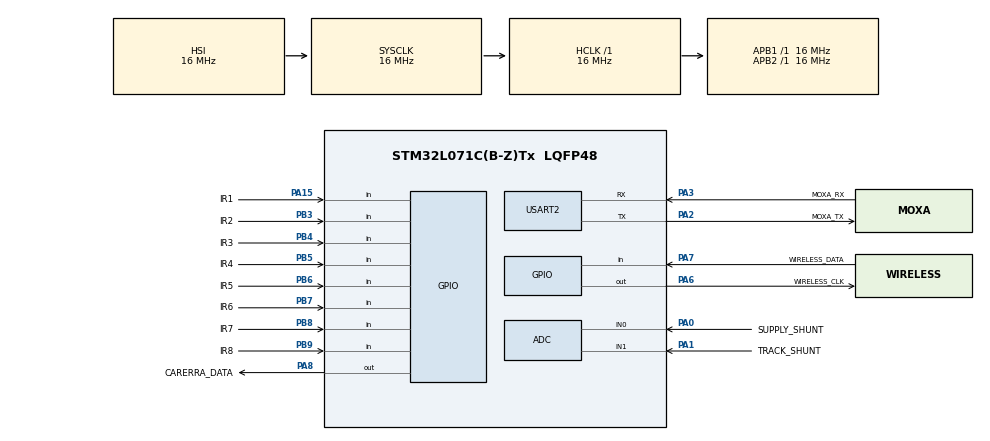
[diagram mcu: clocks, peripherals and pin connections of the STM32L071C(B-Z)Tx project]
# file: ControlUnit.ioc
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ADC.ClockPrescaler=ADC_CLOCK_SYNC_PCLK_DIV2
ADC.DMAContinuousRequests=ENABLE
ADC.ExternalTrigConv=ADC_EXTERNALTRIGCONV_T2_CC4
ADC.LowPowerFrequencyMode=DISABLE
ADC.Overrun=ADC_OVR_DATA_OVERWRITTEN
ADC.SamplingTime=ADC_SAMPLETIME_79CYCLES_5
Dma.ADC.0.Direction=DMA_PERIPH_TO_MEMORY
Dma.ADC.0.Instance=DMA1_Channel1
Dma.ADC.0.MemDataAlignment=DMA_MDATAALIGN_HALFWORD
Dma.ADC.0.MemInc=DMA_MINC_ENABLE
Dma.ADC.0.Mode=DMA_CIRCULAR
Dma.ADC.0.PeriphDataAlignment=DMA_PDATAALIGN_HALFWORD
Dma.ADC.0.PeriphInc=DMA_PINC_DISABLE
Dma.ADC.0.Priority=DMA_PRIORITY_LOW
Dma.Request0=ADC
Mcu.Family=STM32L0
Mcu.Name=STM32L071C(B-Z)Tx
Mcu.Package=LQFP48
NVIC.DMA1_Channel1_IRQn=true\:0\:0\:false\:false\:true\:false\:true\:true
NVIC.USART2_IRQn=true\:0\:0\:false\:false\:true\:true\:true\:true
PA0.GPIO_Label=SUPPLY_SHUNT
PA0.Mode=IN0
PA0.Signal=ADC_IN0
PA1.GPIO_Label=TRACK_SHUNT
PA1.Mode=IN1
PA1.Signal=ADC_IN1
PA15.GPIO_Label=IR1
PA15.Signal=GPIO_Input
PA2.GPIO_Label=MOXA_TX
PA2.Mode=Asynchronous
PA2.Signal=USART2_TX
PA3.GPIO_Label=MOXA_RX
PA3.Mode=Asynchronous
PA3.Signal=USART2_RX
PA6.GPIO_Label=WIRELESS_CLK
PA6.Signal=GPIO_Output
PA7.GPIO_Label=WIRELESS_DATA
PA7.Signal=GPIO_Input
PA8.GPIO_Label=CARERRA_DATA
PA8.Signal=GPIO_Output
PB3.GPIO_Label=IR2
PB3.Signal=GPIO_Input
PB4.GPIO_Label=IR3
PB4.Signal=GPIO_Input
PB5.GPIO_Label=IR4
PB5.Signal=GPIO_Input
PB6.GPIO_Label=IR5
PB6.Signal=GPIO_Input
PB7.GPIO_Label=IR6
PB7.Signal=GPIO_Input
PB8.GPIO_Label=IR7
PB8.Signal=GPIO_Input
PB9.GPIO_Label=IR8
PB9.Signal=GPIO_Input
ProjectManager.HeapSize=0x200
ProjectManager.StackSize=0x400
ProjectManager.TargetToolchain=CMake
RCC.AHBFreq_Value=16000000
RCC.APB1Freq_Value=16000000
RCC.APB1TimFreq_Value=16000000
RCC.APB2Freq_Value=16000000
RCC.APB2TimFreq_Value=16000000
RCC.HSE_VALUE=8000000
RCC.HSI16_VALUE=16000000
RCC.HSI_VALUE=16000000
RCC.LSE_VALUE=32768
RCC.MSI_VALUE=2097000
RCC.SYSCLKFreq_VALUE=16000000
RCC.SYSCLKSource=RCC_SYSCLKSOURCE_HSI
RCC.VCOOutputFreq_Value=48000000
TIM2.Channel-Output\ Compare4\ No\ Output=TIM_CHANNEL_4
TIM2.Period=65535
TIM2.Prescaler=15
TIM2.Pulse-Output\ Compare4\ No\ Output=20
USART2.VirtualMode-Asynchronous=VM_ASYNC
VP_TIM2_VS_ClockSourceINT.Mode=Internal
VP_TIM2_VS_no_output4.Mode=Output Compare4 No Output
board=custom

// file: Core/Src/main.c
/* USER CODE BEGIN Header */
/**
 ******************************************************************************
 * @file           : main.c
 * @brief          : Main program body
 ******************************************************************************
 * @attention
 *
 * Copyright (c) 2026 STMicroelectronics.
 * All rights reserved.
 *
 * This software is licensed under terms that can be found in the LICENSE file
 * in the root directory of this software component.
 * If no LICENSE file comes with this software, it is provided AS-IS.
 *
 ******************************************************************************
 */
/* USER CODE END Header */
#include "main.h"
#include "adc.h"
#include "dma.h"
#include "tim.h"
#include "usart.h"
#include "gpio.h"

/* USER CODE BEGIN Includes */
#include "ControlUnit.h"

/* USER CODE END Includes */

void SystemClock_Config(void);

int main(void)
{

  /* MCU Configuration--------------------------------------------------------*/

  /* Reset of all peripherals, Initializes the Flash interface and the Systick. */
  HAL_Init();

  /* Configure the system clock */
  SystemClock_Config();

  /* Initialize all configured peripherals */
  MX_GPIO_Init();
  MX_DMA_Init();
  MX_ADC_Init();
  MX_USART2_UART_Init();
  MX_TIM2_Init();
  /* USER CODE BEGIN 2 */
  ControlUnit_Init();

  /* USER CODE END 2 */

  /* Infinite loop */
  while (1)
  {

    /* USER CODE BEGIN 3 */
    ControlUnit_Tick();
  }
  /* USER CODE END 3 */
}

void SystemClock_Config(void)
{
  RCC_OscInitTypeDef RCC_OscInitStruct = {0};
  RCC_ClkInitTypeDef RCC_ClkInitStruct = {0};
  RCC_PeriphCLKInitTypeDef PeriphClkInit = {0};

  /** Configure the main internal regulator output voltage
  */
  __HAL_PWR_VOLTAGESCALING_CONFIG(PWR_REGULATOR_VOLTAGE_SCALE1);

  /** Initializes the RCC Oscillators according to the specified parameters
  * in the RCC_OscInitTypeDef structure.
  */
  RCC_OscInitStruct.OscillatorType = RCC_OSCILLATORTYPE_HSI;
  RCC_OscInitStruct.HSIState = RCC_HSI_ON;
  RCC_OscInitStruct.HSICalibrationValue = RCC_HSICALIBRATION_DEFAULT;
  RCC_OscInitStruct.PLL.PLLState = RCC_PLL_NONE;
  if (HAL_RCC_OscConfig(&RCC_OscInitStruct) != HAL_OK)
  {
    Error_Handler();
  }

  /** Initializes the CPU, AHB and APB buses clocks
  */
  RCC_ClkInitStruct.ClockType = RCC_CLOCKTYPE_HCLK|RCC_CLOCKTYPE_SYSCLK
                              |RCC_CLOCKTYPE_PCLK1|RCC_CLOCKTYPE_PCLK2;
  RCC_ClkInitStruct.SYSCLKSource = RCC_SYSCLKSOURCE_HSI;
  RCC_ClkInitStruct.AHBCLKDivider = RCC_SYSCLK_DIV1;
  RCC_ClkInitStruct.APB1CLKDivider = RCC_HCLK_DIV1;
  RCC_ClkInitStruct.APB2CLKDivider = RCC_HCLK_DIV1;

  if (HAL_RCC_ClockConfig(&RCC_ClkInitStruct, FLASH_LATENCY_0) != HAL_OK)
  {
    Error_Handler();
  }
  PeriphClkInit.PeriphClockSelection = RCC_PERIPHCLK_USART2;
  PeriphClkInit.Usart2ClockSelection = RCC_USART2CLKSOURCE_PCLK1;
  if (HAL_RCCEx_PeriphCLKConfig(&PeriphClkInit) != HAL_OK)
  {
    Error_Handler();
  }
}

void Error_Handler(void)
{
  __disable_irq();
  while (1)
  {
  }
}
